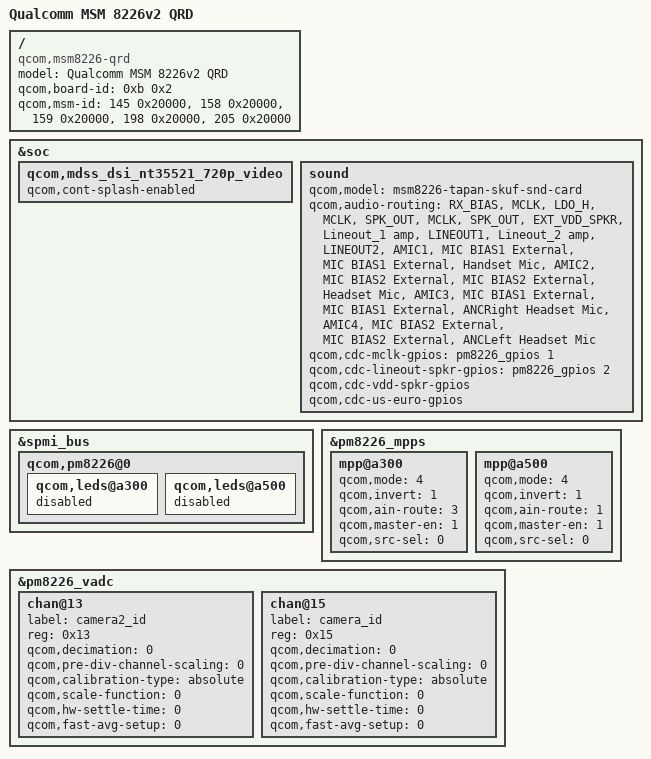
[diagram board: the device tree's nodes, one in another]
/* Copyright (c) 2013, The Linux Foundation. All rights reserved.
 *
 * This program is free software; you can redistribute it and/or modify
 * it under the terms of the GNU General Public License version 2 and
 * only version 2 as published by the Free Software Foundation.
 *
 * This program is distributed in the hope that it will be useful,
 * but WITHOUT ANY WARRANTY; without even the implied warranty of
 * MERCHANTABILITY or FITNESS FOR A PARTICULAR PURPOSE.  See the
 * GNU General Public License for more details.
 */

/dts-v1/;
/include/ "msm8226-v2.dtsi"
/include/ "msm8226-qrd.dtsi"
/include/ "dsi-panel-nt35521-720p-video.dtsi"

/ {
	model = "Qualcomm MSM 8226v2 QRD";
	compatible = "qcom,msm8226-qrd", "qcom,msm8226", "qcom,qrd";
	qcom,board-id = <0xb 0x2>;
	qcom,msm-id = <145 0x20000>,
		      <158 0x20000>,
		      <159 0x20000>,
		      <198 0x20000>,
		      <205 0x20000>;
};

&soc {
	qcom,mdss_dsi_nt35521_720p_video {
		status = "ok";
		qcom,cont-splash-enabled;
	};

	sound {
		qcom,model = "msm8226-tapan-skuf-snd-card";

		qcom,audio-routing =
			"RX_BIAS", "MCLK",
			"LDO_H", "MCLK",
			"SPK_OUT", "MCLK",
			"SPK_OUT", "EXT_VDD_SPKR",
			"Lineout_1 amp", "LINEOUT1",
			"Lineout_2 amp", "LINEOUT2",
			"AMIC1", "MIC BIAS1 External",
			"MIC BIAS1 External", "Handset Mic",
			"AMIC2", "MIC BIAS2 External",
			"MIC BIAS2 External", "Headset Mic",
			"AMIC3", "MIC BIAS1 External",
			"MIC BIAS1 External", "ANCRight Headset Mic",
			"AMIC4", "MIC BIAS2 External",
			"MIC BIAS2 External", "ANCLeft Headset Mic";

		qcom,cdc-mclk-gpios = <&pm8226_gpios 1 0>;
		qcom,cdc-lineout-spkr-gpios = <&pm8226_gpios 2 0>;
		qcom,cdc-vdd-spkr-gpios;
		qcom,cdc-us-euro-gpios;
	};
};

&spmi_bus {
	qcom,pm8226@0 {
		qcom,leds@a300 {
			status = "disabled";
		};

		qcom,leds@a500 {
			status = "disabled";
		};
	};
};

&pm8226_mpps {
	mpp@a300 { /* MPP 4 */
		/* camera2_id */
		qcom,mode = <4>; /* AIN input */
		qcom,invert = <1>; /* Enable MPP */
		qcom,ain-route = <3>; /* AMUX 8 */
		qcom,master-en = <1>;
		qcom,src-sel = <0>; /* Function constant */
	};

	mpp@a500 { /* MPP 6 */
		/* camera_id */
		qcom,mode = <4>; /* AIN input */
		qcom,invert = <1>; /* Enable MPP */
		qcom,ain-route = <1>; /* AMUX 6 */
		qcom,master-en = <1>;
		qcom,src-sel = <0>; /* Function constant */
	};

};

&pm8226_vadc {
	chan@13 {
		label = "camera2_id";
		reg = <0x13>;
		qcom,decimation = <0>;
		qcom,pre-div-channel-scaling = <0>;
		qcom,calibration-type = "absolute";
		qcom,scale-function = <0>;
		qcom,hw-settle-time = <0>;
		qcom,fast-avg-setup = <0>;
	};

	chan@15 {
		label = "camera_id";
		reg = <0x15>;
		qcom,decimation = <0>;
		qcom,pre-div-channel-scaling = <0>;
		qcom,calibration-type = "absolute";
		qcom,scale-function = <0>;
		qcom,hw-settle-time = <0>;
		qcom,fast-avg-setup = <0>;
	};
};
